# ITM_356.0 register map
Vendor: Texas Instruments
Peripheral module from a debugger description file (folder MSP432).
Registers are 32-bit, access not given, no defined reset value unless marked. A register's access mark holds for its fields unless they carry their own. Offsets are as the file gives them; lines under a group give offsets from that group; [hi:lo] are bit positions; {n}, {i} and the like mark numbered series; 'fields as' and 'values as' point back to an identical list; <NAME> marks a mode.

## ITM
{0x0+4i} ITM_STIM{i} (i=0..31) — ITM Stimulus Port {i}
0xE00 ITM_TER — ITM Trace Enable Register
0xE40 ITM_TPR rw — ITM Trace Privilege Register
  [3:0] PRIVMASK — Bit mask to enable tracing on ITM stimulus ports: bit [0] = stimulus ports [7:0], bit [1] = stimulus ports [15:8], bit [2] = stimulus ports [23:16], bit [3] = stimulus ports [31:24].
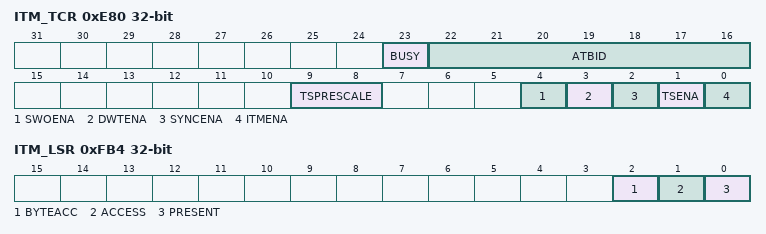
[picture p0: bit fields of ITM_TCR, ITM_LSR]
0xE80 ITM_TCR rw — ITM Trace Control Register
  [23] BUSY — Set when ITM events present and being drained.
  [22:16] ATBID — ATB ID for CoreSight system.
  [9:8] TSPRESCALE — TSPrescale Timestamp prescaler.
    0=en_0b00 (no prescaling); 1=en_0b01 (divide by 4); 2=en_0b10 (divide by 16); 3=en_0b11 (divide by 64)
  [4] SWOENA — Enables asynchronous clocking of the timestamp counter.
  [3] DWTENA — Enables the DWT stimulus.
  [2] SYNCENA — Enables sync packets for TPIU.
  [1] TSENA — Enables differential timestamps. Differential timestamps are emitted when a packet is written to the FIFO with a non-zero timestamp counter, and when the timestamp counter overflows. Timestamps are emitted during idle times after a fixed number of two million cycles. This provides a time reference for packets and inter-packet gaps. If SWOENA (bit [4]) is set, timestamps are triggered by activity on the internal trace bus only. In this case there is no regular timestamp output when the ITM is idle.
  [0] ITMENA — Enable ITM. This is the master enable, and must be set before ITM Stimulus and Trace Enable registers can be written.
0xEF8 ITM_IWR rw — ITM Integration Write Register
  [0] ATVALIDM — When the integration mode is set: 0 = ATVALIDM clear. 1 = ATVALIDM set.
    0=en_0b0 (ATVALIDM clear); 1=en_0b1 (ATVALIDM set)
0xF00 ITM_IMCR rw — ITM Integration Mode Control Register
  [0] INTEGRATION
    0=en_0b0 (ATVALIDM normal); 1=en_0b1 (ATVALIDM driven from Integration Write Register)
0xFB0 ITM_LAR — ITM Lock Access Register
0xFB4 ITM_LSR ro — ITM Lock Status Register
  [2] BYTEACC — You cannot implement 8-bit lock accesses.
  [1] ACCESS — Write access to component is blocked. All writes are ignored, reads are permitted.
  [0] PRESENT — Indicates that a lock mechanism exists for this component.
